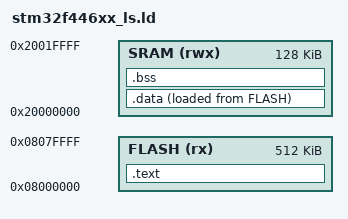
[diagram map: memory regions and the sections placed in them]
ENTRY(Reset_Handler)

MEMORY
{
    FLASH (rx)  : ORIGIN = 0x08000000, LENGTH = 512 * 1024
    SRAM  (rwx) : ORIGIN = 0x20000000, LENGTH = 128 * 1024
}

__max_heap_size  = 0x400;
__max_stack_size = 0x200;

SECTIONS
{
    .text :
    {
        *(.vector_table)
        *(.text)
        *(.text.*)
        *(.rodata)
        *(.rodata.*)
        . = ALIGN(4);
        _etext = .;
    } > FLASH

    .data :
    {
        _sdata = .;
        *(.data)
        *(.data.*)
        . = ALIGN(4);
        _edata = .;
    } > SRAM AT > FLASH

    .bss :
    {
        _sbss = .;
        __bss_start__ = _sbss;
        *(.bss)
        *(.bss.*)
        . = ALIGN(4);
        _ebss = .;
        __bss_end__ = _ebss;
        . = ALIGN(4);
        end = .;
    } > SRAM
}
